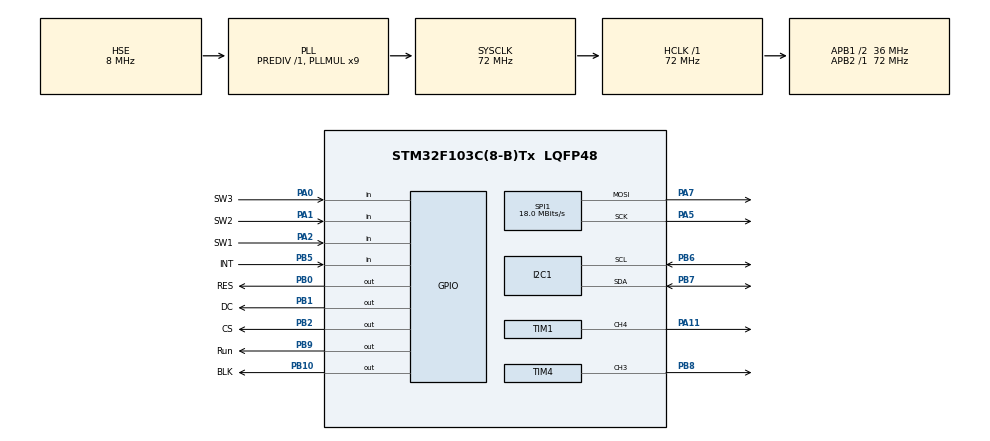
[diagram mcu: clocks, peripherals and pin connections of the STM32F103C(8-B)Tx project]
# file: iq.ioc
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Dma.Request0=TIM1_CH4/TRIG/COM
Dma.TIM1_CH4/TRIG/COM.0.Direction=DMA_MEMORY_TO_PERIPH
Dma.TIM1_CH4/TRIG/COM.0.Instance=DMA1_Channel4
Dma.TIM1_CH4/TRIG/COM.0.MemDataAlignment=DMA_MDATAALIGN_WORD
Dma.TIM1_CH4/TRIG/COM.0.MemInc=DMA_MINC_ENABLE
Dma.TIM1_CH4/TRIG/COM.0.Mode=DMA_NORMAL
Dma.TIM1_CH4/TRIG/COM.0.PeriphDataAlignment=DMA_PDATAALIGN_WORD
Dma.TIM1_CH4/TRIG/COM.0.PeriphInc=DMA_PINC_DISABLE
Dma.TIM1_CH4/TRIG/COM.0.Priority=DMA_PRIORITY_MEDIUM
I2C1.DualAddressMode=I2C_DUALADDRESS_DISABLE
I2C1.I2C_Mode=I2C_Standard
I2C1.NoStretchMode=I2C_NOSTRETCH_DISABLE
Mcu.Family=STM32F1
Mcu.Name=STM32F103C(8-B)Tx
Mcu.Package=LQFP48
NVIC.DMA1_Channel4_IRQn=true\:0\:0\:false\:false\:true\:false\:true\:true
NVIC.PriorityGroup=NVIC_PRIORITYGROUP_4
NVIC.TIM3_IRQn=true\:5\:0\:true\:false\:true\:true\:true\:true
PA0-WKUP.GPIO_Label=SW3
PA0-WKUP.GPIO_PuPd=GPIO_PULLUP
PA0-WKUP.Signal=GPIO_Input
PA1.GPIO_Label=SW2
PA1.GPIO_PuPd=GPIO_PULLUP
PA1.Signal=GPIO_Input
PA11.Signal=S_TIM1_CH4
PA13.Mode=Serial_Wire
PA13.Signal=SYS_JTMS-SWDIO
PA14.Mode=Serial_Wire
PA14.Signal=SYS_JTCK-SWCLK
PA2.GPIO_Label=SW1
PA2.GPIO_PuPd=GPIO_PULLUP
PA2.Signal=GPIO_Input
PA5.Mode=TX_Only_Simplex_Unidirect_Master
PA5.Signal=SPI1_SCK
PA7.Mode=TX_Only_Simplex_Unidirect_Master
PA7.Signal=SPI1_MOSI
PB0.GPIO_Label=RES
PB0.GPIO_Speed=GPIO_SPEED_FREQ_HIGH
PB0.Signal=GPIO_Output
PB1.GPIO_Label=DC
PB1.GPIO_Speed=GPIO_SPEED_FREQ_HIGH
PB1.Signal=GPIO_Output
PB10.GPIO_Label=BLK
PB10.GPIO_Speed=GPIO_SPEED_FREQ_HIGH
PB10.Signal=GPIO_Output
PB2.GPIO_Label=CS
PB2.GPIO_Speed=GPIO_SPEED_FREQ_HIGH
PB2.Signal=GPIO_Output
PB5.GPIO_Label=INT
PB5.GPIO_PuPd=GPIO_PULLUP
PB5.Signal=GPIO_Input
PB6.Mode=I2C
PB6.Signal=I2C1_SCL
PB7.Mode=I2C
PB7.Signal=I2C1_SDA
PB8.Signal=S_TIM4_CH3
PB9.GPIO_Label=Run
PB9.GPIO_ModeDefaultOutputPP=GPIO_MODE_OUTPUT_PP
PB9.GPIO_PuPd=GPIO_NOPULL
PB9.GPIO_Speed=GPIO_SPEED_FREQ_HIGH
PB9.PinState=GPIO_PIN_SET
PB9.Signal=GPIO_Output
PC14-OSC32_IN.Mode=LSE-External-Oscillator
PC14-OSC32_IN.Signal=RCC_OSC32_IN
PC15-OSC32_OUT.Mode=LSE-External-Oscillator
PC15-OSC32_OUT.Signal=RCC_OSC32_OUT
PD0-OSC_IN.Mode=HSE-External-Oscillator
PD0-OSC_IN.Signal=RCC_OSC_IN
PD1-OSC_OUT.Mode=HSE-External-Oscillator
PD1-OSC_OUT.Signal=RCC_OSC_OUT
ProjectManager.HeapSize=0x200
ProjectManager.StackSize=0x400
ProjectManager.TargetToolchain=MDK-ARM V5.32
RCC.AHBFreq_Value=72000000
RCC.APB1CLKDivider=RCC_HCLK_DIV2
RCC.APB1Freq_Value=36000000
RCC.APB1TimFreq_Value=72000000
RCC.APB2Freq_Value=72000000
RCC.APB2TimFreq_Value=72000000
RCC.HCLKFreq_Value=72000000
RCC.PLLMUL=RCC_PLL_MUL9
RCC.PLLSourceVirtual=RCC_PLLSOURCE_HSE
RCC.SYSCLKFreq_VALUE=72000000
RCC.SYSCLKSource=RCC_SYSCLKSOURCE_PLLCLK
RCC.USBFreq_Value=72000000
SH.S_TIM1_CH4.0=TIM1_CH4,PWM Generation4 CH4
SH.S_TIM4_CH3.0=TIM4_CH3,PWM Generation3 CH3
SPI1.BaudRatePrescaler=SPI_BAUDRATEPRESCALER_4
SPI1.CLKPhase=SPI_PHASE_2EDGE
SPI1.CLKPolarity=SPI_POLARITY_HIGH
SPI1.CRCCalculation=SPI_CRCCALCULATION_DISABLE
SPI1.CalculateBaudRate=18.0 MBits/s
SPI1.Direction=SPI_DIRECTION_2LINES
SPI1.Mode=SPI_MODE_MASTER
SPI1.VirtualType=VM_MASTER
TIM1.Channel-PWM\ Generation4\ CH4=TIM_CHANNEL_4
TIM1.Period=89
TIM3.AutoReloadPreload=TIM_AUTORELOAD_PRELOAD_ENABLE
TIM3.Period=999
TIM3.Prescaler=71
TIM4.Channel-PWM\ Generation3\ CH3=TIM_CHANNEL_3
VP_TIM1_VS_ClockSourceINT.Mode=Internal
VP_TIM3_VS_ClockSourceINT.Mode=Internal
board=custom

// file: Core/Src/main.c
/* USER CODE BEGIN Header */
/**
  ******************************************************************************
  * @file           : main.c
  * @brief          : Main program body
  ******************************************************************************
  * @attention
  *
  * Copyright (c) 2024 STMicroelectronics.
  * All rights reserved.
  *
  * This software is licensed under terms that can be found in the LICENSE file
  * in the root directory of this software component.
  * If no LICENSE file comes with this software, it is provided AS-IS.
  *
  ******************************************************************************
  */
/* USER CODE END Header */
#include "main.h"

/* USER CODE BEGIN Includes */
#include "app.h"
/* USER CODE END Includes */

I2C_HandleTypeDef hi2c1;

SPI_HandleTypeDef hspi1;

TIM_HandleTypeDef htim1;
TIM_HandleTypeDef htim3;
TIM_HandleTypeDef htim4;
DMA_HandleTypeDef hdma_tim1_ch4_trig_com;

void SystemClock_Config(void);
static void MX_GPIO_Init(void);
static void MX_DMA_Init(void);
static void MX_I2C1_Init(void);
static void MX_TIM3_Init(void);
static void MX_TIM4_Init(void);
static void MX_SPI1_Init(void);
static void MX_TIM1_Init(void);

int main(void)
{

  /* MCU Configuration--------------------------------------------------------*/

  /* Reset of all peripherals, Initializes the Flash interface and the Systick. */
  HAL_Init();

  /* Configure the system clock */
  SystemClock_Config();

  /* Initialize all configured peripherals */
  MX_GPIO_Init();
  MX_DMA_Init();
  MX_I2C1_Init();
  MX_TIM3_Init();
  MX_TIM4_Init();
  MX_SPI1_Init();
  MX_TIM1_Init();
  /* USER CODE BEGIN 2 */
	App();
  /* USER CODE END 2 */

  /* Infinite loop */
  while (1)
  {

  }
}

void SystemClock_Config(void)
{
  RCC_OscInitTypeDef RCC_OscInitStruct = {0};
  RCC_ClkInitTypeDef RCC_ClkInitStruct = {0};

  /** Initializes the RCC Oscillators according to the specified parameters
  * in the RCC_OscInitTypeDef structure.
  */
  RCC_OscInitStruct.OscillatorType = RCC_OSCILLATORTYPE_HSE;
  RCC_OscInitStruct.HSEState = RCC_HSE_ON;
  RCC_OscInitStruct.HSEPredivValue = RCC_HSE_PREDIV_DIV1;
  RCC_OscInitStruct.HSIState = RCC_HSI_ON;
  RCC_OscInitStruct.PLL.PLLState = RCC_PLL_ON;
  RCC_OscInitStruct.PLL.PLLSource = RCC_PLLSOURCE_HSE;
  RCC_OscInitStruct.PLL.PLLMUL = RCC_PLL_MUL9;
  if (HAL_RCC_OscConfig(&RCC_OscInitStruct) != HAL_OK)
  {
    Error_Handler();
  }

  /** Initializes the CPU, AHB and APB buses clocks
  */
  RCC_ClkInitStruct.ClockType = RCC_CLOCKTYPE_HCLK|RCC_CLOCKTYPE_SYSCLK
                              |RCC_CLOCKTYPE_PCLK1|RCC_CLOCKTYPE_PCLK2;
  RCC_ClkInitStruct.SYSCLKSource = RCC_SYSCLKSOURCE_PLLCLK;
  RCC_ClkInitStruct.AHBCLKDivider = RCC_SYSCLK_DIV1;
  RCC_ClkInitStruct.APB1CLKDivider = RCC_HCLK_DIV2;
  RCC_ClkInitStruct.APB2CLKDivider = RCC_HCLK_DIV1;

  if (HAL_RCC_ClockConfig(&RCC_ClkInitStruct, FLASH_LATENCY_2) != HAL_OK)
  {
    Error_Handler();
  }
}

static void MX_I2C1_Init(void)
{

  hi2c1.Instance = I2C1;
  hi2c1.Init.ClockSpeed = 100000;
  hi2c1.Init.DutyCycle = I2C_DUTYCYCLE_2;
  hi2c1.Init.OwnAddress1 = 0;
  hi2c1.Init.AddressingMode = I2C_ADDRESSINGMODE_7BIT;
  hi2c1.Init.DualAddressMode = I2C_DUALADDRESS_DISABLE;
  hi2c1.Init.OwnAddress2 = 0;
  hi2c1.Init.GeneralCallMode = I2C_GENERALCALL_DISABLE;
  hi2c1.Init.NoStretchMode = I2C_NOSTRETCH_DISABLE;
  if (HAL_I2C_Init(&hi2c1) != HAL_OK)
  {
    Error_Handler();
  }

}

static void MX_SPI1_Init(void)
{

  /* SPI1 parameter configuration*/
  hspi1.Instance = SPI1;
  hspi1.Init.Mode = SPI_MODE_MASTER;
  hspi1.Init.Direction = SPI_DIRECTION_2LINES;
  hspi1.Init.DataSize = SPI_DATASIZE_8BIT;
  hspi1.Init.CLKPolarity = SPI_POLARITY_HIGH;
  hspi1.Init.CLKPhase = SPI_PHASE_2EDGE;
  hspi1.Init.NSS = SPI_NSS_SOFT;
  hspi1.Init.BaudRatePrescaler = SPI_BAUDRATEPRESCALER_4;
  hspi1.Init.FirstBit = SPI_FIRSTBIT_MSB;
  hspi1.Init.TIMode = SPI_TIMODE_DISABLE;
  hspi1.Init.CRCCalculation = SPI_CRCCALCULATION_DISABLE;
  hspi1.Init.CRCPolynomial = 10;
  if (HAL_SPI_Init(&hspi1) != HAL_OK)
  {
    Error_Handler();
  }

}

static void MX_TIM1_Init(void)
{

  TIM_ClockConfigTypeDef sClockSourceConfig = {0};
  TIM_MasterConfigTypeDef sMasterConfig = {0};
  TIM_OC_InitTypeDef sConfigOC = {0};
  TIM_BreakDeadTimeConfigTypeDef sBreakDeadTimeConfig = {0};

  htim1.Instance = TIM1;
  htim1.Init.Prescaler = 0;
  htim1.Init.CounterMode = TIM_COUNTERMODE_UP;
  htim1.Init.Period = 89;
  htim1.Init.ClockDivision = TIM_CLOCKDIVISION_DIV1;
  htim1.Init.RepetitionCounter = 0;
  htim1.Init.AutoReloadPreload = TIM_AUTORELOAD_PRELOAD_DISABLE;
  if (HAL_TIM_Base_Init(&htim1) != HAL_OK)
  {
    Error_Handler();
  }
  sClockSourceConfig.ClockSource = TIM_CLOCKSOURCE_INTERNAL;
  if (HAL_TIM_ConfigClockSource(&htim1, &sClockSourceConfig) != HAL_OK)
  {
    Error_Handler();
  }
  if (HAL_TIM_PWM_Init(&htim1) != HAL_OK)
  {
    Error_Handler();
  }
  sMasterConfig.MasterOutputTrigger = TIM_TRGO_RESET;
  sMasterConfig.MasterSlaveMode = TIM_MASTERSLAVEMODE_DISABLE;
  if (HAL_TIMEx_MasterConfigSynchronization(&htim1, &sMasterConfig) != HAL_OK)
  {
    Error_Handler();
  }
  sConfigOC.OCMode = TIM_OCMODE_PWM1;
  sConfigOC.Pulse = 0;
  sConfigOC.OCPolarity = TIM_OCPOLARITY_HIGH;
  sConfigOC.OCFastMode = TIM_OCFAST_DISABLE;
  sConfigOC.OCIdleState = TIM_OCIDLESTATE_RESET;
  sConfigOC.OCNIdleState = TIM_OCNIDLESTATE_RESET;
  if (HAL_TIM_PWM_ConfigChannel(&htim1, &sConfigOC, TIM_CHANNEL_4) != HAL_OK)
  {
    Error_Handler();
  }
  sBreakDeadTimeConfig.OffStateRunMode = TIM_OSSR_DISABLE;
  sBreakDeadTimeConfig.OffStateIDLEMode = TIM_OSSI_DISABLE;
  sBreakDeadTimeConfig.LockLevel = TIM_LOCKLEVEL_OFF;
  sBreakDeadTimeConfig.DeadTime = 0;
  sBreakDeadTimeConfig.BreakState = TIM_BREAK_DISABLE;
  sBreakDeadTimeConfig.BreakPolarity = TIM_BREAKPOLARITY_HIGH;
  sBreakDeadTimeConfig.AutomaticOutput = TIM_AUTOMATICOUTPUT_DISABLE;
  if (HAL_TIMEx_ConfigBreakDeadTime(&htim1, &sBreakDeadTimeConfig) != HAL_OK)
  {
    Error_Handler();
  }
  HAL_TIM_MspPostInit(&htim1);

}

static void MX_TIM3_Init(void)
{

  TIM_ClockConfigTypeDef sClockSourceConfig = {0};
  TIM_MasterConfigTypeDef sMasterConfig = {0};

  htim3.Instance = TIM3;
  htim3.Init.Prescaler = 71;
  htim3.Init.CounterMode = TIM_COUNTERMODE_UP;
  htim3.Init.Period = 999;
  htim3.Init.ClockDivision = TIM_CLOCKDIVISION_DIV1;
  htim3.Init.AutoReloadPreload = TIM_AUTORELOAD_PRELOAD_ENABLE;
  if (HAL_TIM_Base_Init(&htim3) != HAL_OK)
  {
    Error_Handler();
  }
  sClockSourceConfig.ClockSource = TIM_CLOCKSOURCE_INTERNAL;
  if (HAL_TIM_ConfigClockSource(&htim3, &sClockSourceConfig) != HAL_OK)
  {
    Error_Handler();
  }
  sMasterConfig.MasterOutputTrigger = TIM_TRGO_RESET;
  sMasterConfig.MasterSlaveMode = TIM_MASTERSLAVEMODE_DISABLE;
  if (HAL_TIMEx_MasterConfigSynchronization(&htim3, &sMasterConfig) != HAL_OK)
  {
    Error_Handler();
  }

}

static void MX_TIM4_Init(void)
{

  TIM_MasterConfigTypeDef sMasterConfig = {0};
  TIM_OC_InitTypeDef sConfigOC = {0};

  htim4.Instance = TIM4;
  htim4.Init.Prescaler = 0;
  htim4.Init.CounterMode = TIM_COUNTERMODE_UP;
  htim4.Init.Period = 65535;
  htim4.Init.ClockDivision = TIM_CLOCKDIVISION_DIV1;
  htim4.Init.AutoReloadPreload = TIM_AUTORELOAD_PRELOAD_DISABLE;
  if (HAL_TIM_PWM_Init(&htim4) != HAL_OK)
  {
    Error_Handler();
  }
  sMasterConfig.MasterOutputTrigger = TIM_TRGO_RESET;
  sMasterConfig.MasterSlaveMode = TIM_MASTERSLAVEMODE_DISABLE;
  if (HAL_TIMEx_MasterConfigSynchronization(&htim4, &sMasterConfig) != HAL_OK)
  {
    Error_Handler();
  }
  sConfigOC.OCMode = TIM_OCMODE_PWM1;
  sConfigOC.Pulse = 0;
  sConfigOC.OCPolarity = TIM_OCPOLARITY_HIGH;
  sConfigOC.OCFastMode = TIM_OCFAST_DISABLE;
  if (HAL_TIM_PWM_ConfigChannel(&htim4, &sConfigOC, TIM_CHANNEL_3) != HAL_OK)
  {
    Error_Handler();
  }
  HAL_TIM_MspPostInit(&htim4);

}

static void MX_DMA_Init(void)
{

  /* DMA controller clock enable */
  __HAL_RCC_DMA1_CLK_ENABLE();

  /* DMA interrupt init */
  /* DMA1_Channel4_IRQn interrupt configuration */
  HAL_NVIC_SetPriority(DMA1_Channel4_IRQn, 0, 0);
  HAL_NVIC_EnableIRQ(DMA1_Channel4_IRQn);

}

static void MX_GPIO_Init(void)
{
  GPIO_InitTypeDef GPIO_InitStruct = {0};

  /* GPIO Ports Clock Enable */
  __HAL_RCC_GPIOC_CLK_ENABLE();
  __HAL_RCC_GPIOD_CLK_ENABLE();
  __HAL_RCC_GPIOA_CLK_ENABLE();
  __HAL_RCC_GPIOB_CLK_ENABLE();

  /*Configure GPIO pin Output Level */
  HAL_GPIO_WritePin(GPIOB, RES_Pin|DC_Pin|CS_Pin|BLK_Pin, GPIO_PIN_RESET);

  /*Configure GPIO pin Output Level */
  HAL_GPIO_WritePin(Run_GPIO_Port, Run_Pin, GPIO_PIN_SET);

  /*Configure GPIO pins : SW3_Pin SW2_Pin SW1_Pin */
  GPIO_InitStruct.Pin = SW3_Pin|SW2_Pin|SW1_Pin;
  GPIO_InitStruct.Mode = GPIO_MODE_INPUT;
  GPIO_InitStruct.Pull = GPIO_PULLUP;
  HAL_GPIO_Init(GPIOA, &GPIO_InitStruct);

  /*Configure GPIO pins : RES_Pin DC_Pin CS_Pin BLK_Pin
                           Run_Pin */
  GPIO_InitStruct.Pin = RES_Pin|DC_Pin|CS_Pin|BLK_Pin
                          |Run_Pin;
  GPIO_InitStruct.Mode = GPIO_MODE_OUTPUT_PP;
  GPIO_InitStruct.Pull = GPIO_NOPULL;
  GPIO_InitStruct.Speed = GPIO_SPEED_FREQ_HIGH;
  HAL_GPIO_Init(GPIOB, &GPIO_InitStruct);

  /*Configure GPIO pin : INT_Pin */
  GPIO_InitStruct.Pin = INT_Pin;
  GPIO_InitStruct.Mode = GPIO_MODE_INPUT;
  GPIO_InitStruct.Pull = GPIO_PULLUP;
  HAL_GPIO_Init(INT_GPIO_Port, &GPIO_InitStruct);

}

void Error_Handler(void)
{
  __disable_irq();
  while (1)
  {
  }
}
